# PIC32CM2532JH01032 register map
Vendor: Microchip Technology; Series: PIC32CMJH01; File version: 0
CPU: CM0+ r0p0, selectable endian, MPU, VTOR, 2 interrupt priority bits, 32 interrupts
Registers are 32-bit, read-write, reset 0x0 unless marked. A register's access mark holds for its fields unless they carry their own. Offsets are from the block's base; [hi:lo] are bit positions; {n}, {i} and the like mark numbered series; 'fields as' and 'values as' point back to an identical list.

## AC — Analog Comparators
Base 0x42004C00
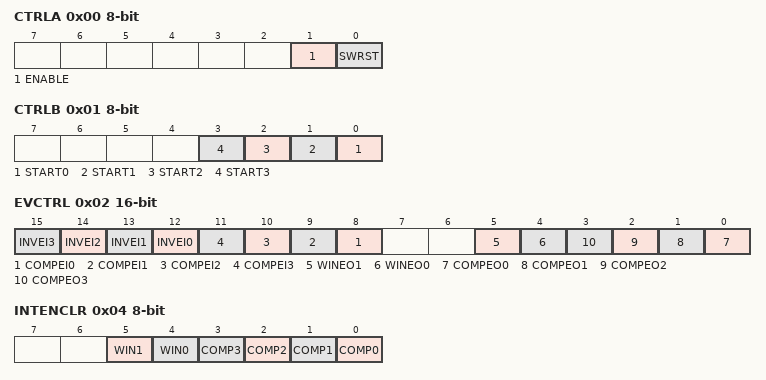
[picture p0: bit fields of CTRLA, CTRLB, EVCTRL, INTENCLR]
0x00 CTRLA 8-bit — Control A
  [1] ENABLE
  [0] SWRST — Software Reset
0x01 CTRLB 8-bit — Control B
  [n] START{n} (n=0..3) — Comparator {n} Start Comparison
0x02 EVCTRL 16-bit — Event Control
  [n+12] INVEI{n} (n=0..3) — Comparator {n} Input Event Invert Enable
  [n+8] COMPEI{n} (n=0..3) — Comparator {n} Event Input Enable
  [5] WINEO1 — Window 1 Event Output Enable
  [4] WINEO0 — Window 0 Event Output Enable
  [n] COMPEO{n} (n=0..3) — Comparator {n} Event Output Enable
0x04 INTENCLR 8-bit — Interrupt Enable Clear
  [5] WIN1 — Window 1 Interrupt Enable
  [4] WIN0 — Window 0 Interrupt Enable
  [n] COMP{n} (n=0..3) — Comparator {n} Interrupt Enable
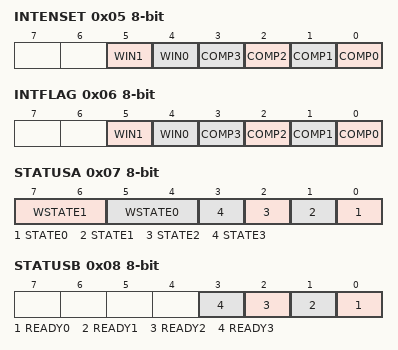
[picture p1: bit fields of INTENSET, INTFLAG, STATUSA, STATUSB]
0x05 INTENSET 8-bit — Interrupt Enable Set
  fields as INTENCLR
0x06 INTFLAG 8-bit — Interrupt Flag Status and Clear
  [5] WIN1 — Window 1
  [4] WIN0 — Window 0
  [n] COMP{n} (n=0..3) — Comparator {n}
0x07 STATUSA 8-bit ro
  [7:6] WSTATE1 — Window 1 Current State
    0=ABOVE (Signal is above window1); 1=INSIDE (Signal is inside window1); 2=BELOW (Signal is below window1)
  [5:4] WSTATE0 — Window 0 Current State
    0=ABOVE (Signal is above window0); 1=INSIDE (Signal is inside window0); 2=BELOW (Signal is below window0)
  [n] STATE{n} (n=0..3) — Comparator {n} Current State
0x08 STATUSB 8-bit ro
  [n] READY{n} (n=0..3) — Comparator {n} Ready
0x09 DBGCTRL 8-bit — Debug Control
  [0] DBGRUN — Debug Run
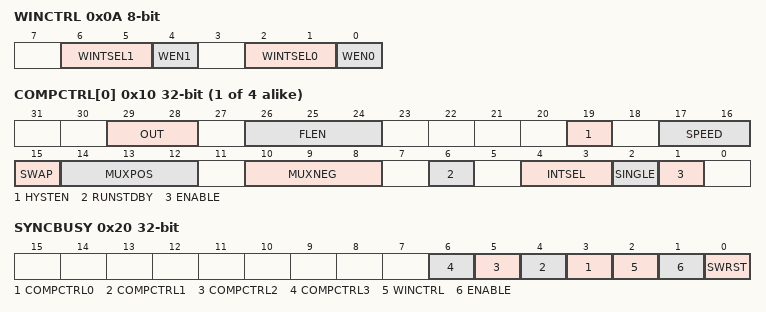
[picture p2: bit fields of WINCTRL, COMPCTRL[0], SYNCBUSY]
0x0A WINCTRL 8-bit — Window Control
  [6:5] WINTSEL1 — Window 1 Interrupt Selection
    0=ABOVE (Interrupt on signal above window1); 1=INSIDE (Interrupt on signal inside window1); 2=BELOW (Interrupt on signal below window1); 3=OUTSIDE (Interrupt on signal outside window1)
  [4] WEN1 — Window 1 Mode Enable
  [2:1] WINTSEL0 — Window 0 Interrupt Selection
    0=ABOVE (Interrupt on signal above window0); 1=INSIDE (Interrupt on signal inside window0); 2=BELOW (Interrupt on signal below window0); 3=OUTSIDE (Interrupt on signal outside window0)
  [0] WEN0 — Window 0 Mode Enable
{0xC+i} SCALER[{i}] (i=0..3) 8-bit — Scaler n
  [5:0] VALUE — Scaler Value
{0x10+4i} COMPCTRL[{i}] (i=0..3) — Comparator Control n
  [29:28] OUT — Output
    0=OFF (The output of COMPn is not routed to the COMPn I/O port); 1=ASYNC (The asynchronous output of COMPn is routed to the COMPn I/O port); 2=SYNC (The synchronous output (including filtering) of COMPn is routed to the COMPn I/O port)
  [26:24] FLEN — Filter Length
    0=OFF (No filtering); 1=MAJ3 (3-bit majority function (2 of 3)); 2=MAJ5 (5-bit majority function (3 of 5))
  [19] HYSTEN — Hysteresis Enable
  [17:16] SPEED — Speed Selection
    0=LOW (Low speed); 3=HIGH (High speed)
  [15] SWAP — Swap Inputs and Invert
  [14:12] MUXPOS — Positive Input Mux Selection
    0=AIN0 (I/O pin 0 for COMPCTRL0/1); 0=AIN4 (I/O pin 0 for COMPCTRL2/3); 1=AIN1 (I/O pin 1 for COMPCTRL0/1); 1=AIN5 (I/O pin 1 for COMPCTRL2/3); 2=AIN2 (I/O pin 2 for COMPCTRL0/1); 2=AIN6 (I/O pin 2 for COMPCTRL2/3); 3=AIN3 (I/O pin 3 for COMPCTRL0/1); 3=AIN7 (I/O pin 3 for COMPCTRL2/3); 4=VSCALE (VDD Scaler)
  [10:8] MUXNEG — Negative Input Mux Selection
    0=AIN0 (I/O pin 0 for COMPCTRL0/1); 0=AIN4 (I/O pin 0 for COMPCTRL2/3); 1=AIN1 (I/O pin 1 for COMPCTRL0/1); 1=AIN5 (I/O pin 1 for COMPCTRL2/3); 2=AIN2 (I/O pin 2 for COMPCTRL0/1); 2=AIN6 (I/O pin 2 for COMPCTRL2/3); 3=AIN3 (I/O pin 3 for COMPCTRL0/1); 3=AIN7 (I/O pin 3 for COMPCTRL2/3); 4=GND (Ground); 5=VSCALE (VDD Scaler); 6=INTREF (Internal Voltage Reference); 7=DAC (DAC Voltage Output)
  [6] RUNSTDBY — Run in Standby
  [4:3] INTSEL — Interrupt Selection
    0=TOGGLE (Interrupt on comparator output toggle); 1=RISING (Interrupt on comparator output rising); 2=FALLING (Interrupt on comparator output falling); 3=EOC (Interrupt on end of comparison (single-shot mode only))
  [2] SINGLE — Single-Shot Mode
  [1] ENABLE
0x20 SYNCBUSY ro — Synchronization Busy
  [n+3] COMPCTRL{n} (n=0..3) — COMPCTRL {n} Synchronization Busy
  [2] WINCTRL — WINCTRL Synchronization Busy
  [1] ENABLE — Enable Synchronization Busy
  [0] SWRST — Software Reset Synchronization Busy

## Notices in the file
Copyright (c) 2023 Microchip Technology Inc.
SPDX-License-Identifier: Apache-2.0
Licensed under the Apache License, Version 2.0 (the "License");
you may not use this file except in compliance with the License.
You may obtain a copy of the License at
http://www.apache.org/licenses/LICENSE-2.0
Unless required by applicable law or agreed to in writing, software
distributed under the License is distributed on an "AS IS" BASIS,
WITHOUT WARRANTIES OR CONDITIONS OF ANY KIND, either express or implied.
See the License for the specific language governing permissions and
limitations under the License.
